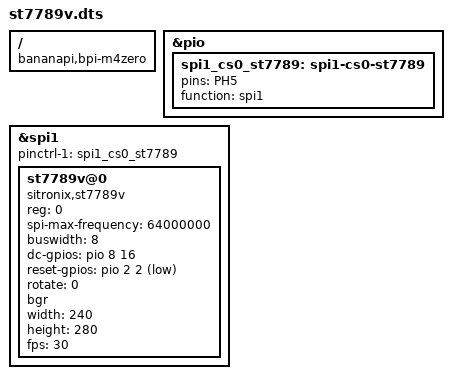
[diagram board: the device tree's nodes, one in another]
/dts-v1/;
/plugin/;

/ {
	compatible = "bananapi,bpi-m4zero", "allwinner,sun50i-h616";

	/* Mux PH5 as SPI1_CS0 — without this the CS pin stays unclaimed
	 * and the display ignores all SPI traffic. */
	fragment@0 {
		target = <&pio>;
		__overlay__ {
			spi1_cs0_st7789: spi1-cs0-st7789 {
				pins = "PH5";
				function = "spi1";
			};
		};
	};

	fragment@1 {
		target = <&spi1>;
		__overlay__ {
			#address-cells = <1>;
			#size-cells = <0>;
			pinctrl-1 = <&spi1_cs0_st7789>;
			pinctrl-names = "default", "default";
			status = "okay";

			st7789v@0 {
				compatible = "sitronix,st7789v";
				reg = <0>;
				spi-max-frequency = <64000000>;
				buswidth = <8>;
				dc-gpios = <&pio 8 16 0>;
				reset-gpios = <&pio 2 2 1>;
				rotate = <0>;
				bgr;
				width = <240>;
				height = <280>;
				fps = <30>;
				status = "okay";
			};
		};
	};
};
